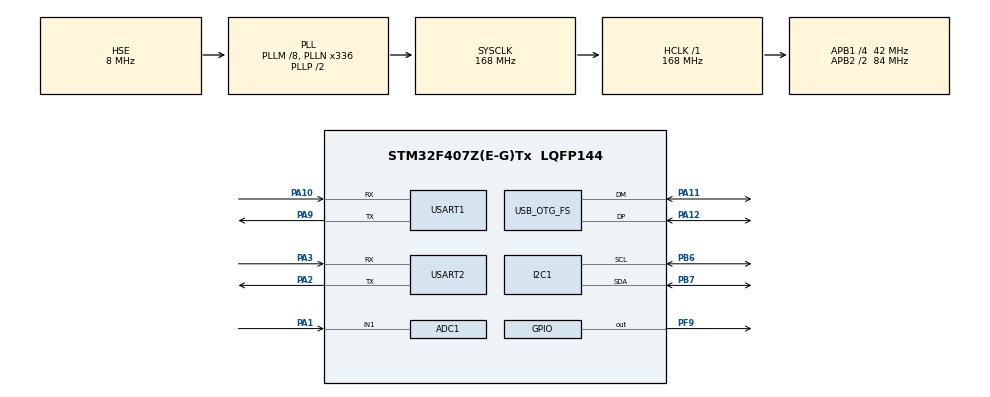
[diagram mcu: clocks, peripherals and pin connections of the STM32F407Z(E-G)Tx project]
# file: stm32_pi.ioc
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ADC1.Channel-0\#ChannelRegularConversion=ADC_CHANNEL_1
ADC1.InjNumberOfConversion=0
ADC1.NbrOfConversionFlag=1
ADC1.Rank-0\#ChannelRegularConversion=1
ADC1.SamplingTime-0\#ChannelRegularConversion=ADC_SAMPLETIME_144CYCLES
ADC1.master=1
Dma.Request0=USART1_TX
Dma.Request1=USART2_TX
Dma.USART1_TX.0.Direction=DMA_MEMORY_TO_PERIPH
Dma.USART1_TX.0.FIFOMode=DMA_FIFOMODE_DISABLE
Dma.USART1_TX.0.Instance=DMA2_Stream7
Dma.USART1_TX.0.MemDataAlignment=DMA_MDATAALIGN_BYTE
Dma.USART1_TX.0.MemInc=DMA_MINC_ENABLE
Dma.USART1_TX.0.Mode=DMA_NORMAL
Dma.USART1_TX.0.PeriphDataAlignment=DMA_PDATAALIGN_BYTE
Dma.USART1_TX.0.PeriphInc=DMA_PINC_DISABLE
Dma.USART1_TX.0.Priority=DMA_PRIORITY_LOW
Dma.USART2_TX.1.Direction=DMA_MEMORY_TO_PERIPH
Dma.USART2_TX.1.FIFOMode=DMA_FIFOMODE_DISABLE
Dma.USART2_TX.1.Instance=DMA1_Stream6
Dma.USART2_TX.1.MemDataAlignment=DMA_MDATAALIGN_BYTE
Dma.USART2_TX.1.MemInc=DMA_MINC_ENABLE
Dma.USART2_TX.1.Mode=DMA_NORMAL
Dma.USART2_TX.1.PeriphDataAlignment=DMA_PDATAALIGN_BYTE
Dma.USART2_TX.1.PeriphInc=DMA_PINC_DISABLE
Dma.USART2_TX.1.Priority=DMA_PRIORITY_LOW
FREERTOS.Tasks01=defaultTask,24,128,StartDefaultTask,Default,NULL,Dynamic,NULL,NULL
I2C1.I2C_Mode=I2C_Fast
Mcu.Family=STM32F4
Mcu.Name=STM32F407Z(E-G)Tx
Mcu.Package=LQFP144
NVIC.DMA1_Stream6_IRQn=true\:5\:0\:false\:false\:true\:true\:false\:true\:true
NVIC.DMA2_Stream7_IRQn=true\:5\:0\:false\:false\:true\:true\:false\:true\:true
NVIC.PriorityGroup=NVIC_PRIORITYGROUP_4
NVIC.TIM6_DAC_IRQn=true\:15\:0\:false\:false\:true\:false\:false\:true\:true
NVIC.TimeBase=TIM6_DAC_IRQn
NVIC.TimeBaseIP=TIM6
NVIC.USART1_IRQn=true\:5\:0\:false\:false\:true\:true\:true\:true\:true
NVIC.USART2_IRQn=true\:5\:0\:false\:false\:true\:true\:true\:true\:true
PA1.Signal=ADCx_IN1
PA10.Mode=Asynchronous
PA10.Signal=USART1_RX
PA11.Mode=Device_Only
PA11.Signal=USB_OTG_FS_DM
PA12.Mode=Device_Only
PA12.Signal=USB_OTG_FS_DP
PA13.Mode=Serial_Wire
PA13.Signal=SYS_JTMS-SWDIO
PA14.Mode=Serial_Wire
PA14.Signal=SYS_JTCK-SWCLK
PA2.Mode=Asynchronous
PA2.Signal=USART2_TX
PA3.Mode=Asynchronous
PA3.Signal=USART2_RX
PA9.Mode=Asynchronous
PA9.Signal=USART1_TX
PB6.Mode=I2C
PB6.Signal=I2C1_SCL
PB7.Mode=I2C
PB7.Signal=I2C1_SDA
PF9.Signal=GPIO_Output
PH0-OSC_IN.Mode=HSE-External-Oscillator
PH0-OSC_IN.Signal=RCC_OSC_IN
PH1-OSC_OUT.Mode=HSE-External-Oscillator
PH1-OSC_OUT.Signal=RCC_OSC_OUT
ProjectManager.HeapSize=0x200
ProjectManager.StackSize=0x400
ProjectManager.TargetToolchain=MDK-ARM V5
RCC.48MHZClocksFreq_Value=48000000
RCC.AHBFreq_Value=168000000
RCC.APB1CLKDivider=RCC_HCLK_DIV4
RCC.APB1Freq_Value=42000000
RCC.APB1TimFreq_Value=84000000
RCC.APB2CLKDivider=RCC_HCLK_DIV2
RCC.APB2Freq_Value=84000000
RCC.APB2TimFreq_Value=168000000
RCC.CortexFreq_Value=168000000
RCC.HCLKFreq_Value=168000000
RCC.HSE_VALUE=8000000
RCC.HSI_VALUE=16000000
RCC.LSE_VALUE=32768
RCC.PLLM=8
RCC.PLLN=336
RCC.PLLQ=7
RCC.SYSCLKFreq_VALUE=168000000
RCC.SYSCLKSource=RCC_SYSCLKSOURCE_PLLCLK
RCC.VCOOutputFreq_Value=336000000
SH.ADCx_IN1.0=ADC1_IN1,IN1
USART1.VirtualMode=VM_ASYNC
USART2.VirtualMode=VM_ASYNC
USB_OTG_FS.VirtualMode=Device_Only
VP_FREERTOS_VS_CMSIS_V2.Mode=CMSIS_V2
VP_SYS_VS_tim6.Mode=TIM6
board=custom

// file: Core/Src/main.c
/* USER CODE BEGIN Header */
/**
  ******************************************************************************
  * @file           : main.c
  * @brief          : Main program body
  ******************************************************************************
  * @attention
  *
  * Copyright (c) 2026 STMicroelectronics.
  * All rights reserved.
  *
  * This software is licensed under terms that can be found in the LICENSE file
  * in the root directory of this software component.
  * If no LICENSE file comes with this software, it is provided AS-IS.
  *
  ******************************************************************************
  */
/* USER CODE END Header */
#include "main.h"
#include "cmsis_os.h"

/* USER CODE BEGIN Includes */
#include "app_main.h"
/* USER CODE END Includes */

ADC_HandleTypeDef hadc1;

I2C_HandleTypeDef hi2c1;

UART_HandleTypeDef huart1;
UART_HandleTypeDef huart2;
DMA_HandleTypeDef hdma_usart1_tx;
DMA_HandleTypeDef hdma_usart2_tx;

PCD_HandleTypeDef hpcd_USB_OTG_FS;

/* Definitions for defaultTask */
osThreadId_t defaultTaskHandle;
const osThreadAttr_t defaultTask_attributes = {
  .name = "defaultTask",
  .stack_size = 128 * 4,
  .priority = (osPriority_t) osPriorityNormal,
};

void SystemClock_Config(void);
static void MX_GPIO_Init(void);
static void MX_DMA_Init(void);
static void MX_USART1_UART_Init(void);
static void MX_USB_OTG_FS_PCD_Init(void);
static void MX_USART2_UART_Init(void);
static void MX_ADC1_Init(void);
static void MX_I2C1_Init(void);
void StartDefaultTask(void *argument);

int main(void)
{

  /* MCU Configuration--------------------------------------------------------*/

  /* Reset of all peripherals, Initializes the Flash interface and the Systick. */
  HAL_Init();

  /* Configure the system clock */
  SystemClock_Config();

  /* Initialize all configured peripherals */
  MX_GPIO_Init();
  MX_DMA_Init();
  MX_USART1_UART_Init();
  MX_USB_OTG_FS_PCD_Init();
  MX_USART2_UART_Init();
  MX_ADC1_Init();
  MX_I2C1_Init();

  /* Init scheduler */
  osKernelInitialize();

  /* Create the thread(s) */
  /* creation of defaultTask */
  defaultTaskHandle = osThreadNew(StartDefaultTask, NULL, &defaultTask_attributes);

  /* USER CODE BEGIN RTOS_THREADS */
  /* add threads, ... */
  App_Main_Init();
  /* USER CODE END RTOS_THREADS */

  /* Start scheduler */
  osKernelStart();
  /* We should never get here as control is now taken by the scheduler */
  /* Infinite loop */
  while (1)
  {

  }
}

void SystemClock_Config(void)
{
  RCC_OscInitTypeDef RCC_OscInitStruct = {0};
  RCC_ClkInitTypeDef RCC_ClkInitStruct = {0};

  /** Configure the main internal regulator output voltage
  */
  __HAL_RCC_PWR_CLK_ENABLE();
  __HAL_PWR_VOLTAGESCALING_CONFIG(PWR_REGULATOR_VOLTAGE_SCALE1);

  /** Initializes the RCC Oscillators according to the specified parameters
  * in the RCC_OscInitTypeDef structure.
  */
  RCC_OscInitStruct.OscillatorType = RCC_OSCILLATORTYPE_HSE;
  RCC_OscInitStruct.HSEState = RCC_HSE_ON;
  RCC_OscInitStruct.PLL.PLLState = RCC_PLL_ON;
  RCC_OscInitStruct.PLL.PLLSource = RCC_PLLSOURCE_HSE;
  RCC_OscInitStruct.PLL.PLLM = 8;
  RCC_OscInitStruct.PLL.PLLN = 336;
  RCC_OscInitStruct.PLL.PLLP = RCC_PLLP_DIV2;
  RCC_OscInitStruct.PLL.PLLQ = 7;
  if (HAL_RCC_OscConfig(&RCC_OscInitStruct) != HAL_OK)
  {
    Error_Handler();
  }

  /** Initializes the CPU, AHB and APB buses clocks
  */
  RCC_ClkInitStruct.ClockType = RCC_CLOCKTYPE_HCLK|RCC_CLOCKTYPE_SYSCLK
                              |RCC_CLOCKTYPE_PCLK1|RCC_CLOCKTYPE_PCLK2;
  RCC_ClkInitStruct.SYSCLKSource = RCC_SYSCLKSOURCE_PLLCLK;
  RCC_ClkInitStruct.AHBCLKDivider = RCC_SYSCLK_DIV1;
  RCC_ClkInitStruct.APB1CLKDivider = RCC_HCLK_DIV4;
  RCC_ClkInitStruct.APB2CLKDivider = RCC_HCLK_DIV2;

  if (HAL_RCC_ClockConfig(&RCC_ClkInitStruct, FLASH_LATENCY_5) != HAL_OK)
  {
    Error_Handler();
  }
}

static void MX_ADC1_Init(void)
{

  ADC_ChannelConfTypeDef sConfig = {0};

  /** Configure the global features of the ADC (Clock, Resolution, Data Alignment and number of conversion)
  */
  hadc1.Instance = ADC1;
  hadc1.Init.ClockPrescaler = ADC_CLOCK_SYNC_PCLK_DIV4;
  hadc1.Init.Resolution = ADC_RESOLUTION_12B;
  hadc1.Init.ScanConvMode = DISABLE;
  hadc1.Init.ContinuousConvMode = DISABLE;
  hadc1.Init.DiscontinuousConvMode = DISABLE;
  hadc1.Init.ExternalTrigConvEdge = ADC_EXTERNALTRIGCONVEDGE_NONE;
  hadc1.Init.ExternalTrigConv = ADC_SOFTWARE_START;
  hadc1.Init.DataAlign = ADC_DATAALIGN_RIGHT;
  hadc1.Init.NbrOfConversion = 1;
  hadc1.Init.DMAContinuousRequests = DISABLE;
  hadc1.Init.EOCSelection = ADC_EOC_SINGLE_CONV;
  if (HAL_ADC_Init(&hadc1) != HAL_OK)
  {
    Error_Handler();
  }

  /** Configure for the selected ADC regular channel its corresponding rank in the sequencer and its sample time.
  */
  sConfig.Channel = ADC_CHANNEL_1;
  sConfig.Rank = 1;
  sConfig.SamplingTime = ADC_SAMPLETIME_144CYCLES;
  if (HAL_ADC_ConfigChannel(&hadc1, &sConfig) != HAL_OK)
  {
    Error_Handler();
  }

}

static void MX_I2C1_Init(void)
{

  hi2c1.Instance = I2C1;
  hi2c1.Init.ClockSpeed = 400000;
  hi2c1.Init.DutyCycle = I2C_DUTYCYCLE_2;
  hi2c1.Init.OwnAddress1 = 0;
  hi2c1.Init.AddressingMode = I2C_ADDRESSINGMODE_7BIT;
  hi2c1.Init.DualAddressMode = I2C_DUALADDRESS_DISABLE;
  hi2c1.Init.OwnAddress2 = 0;
  hi2c1.Init.GeneralCallMode = I2C_GENERALCALL_DISABLE;
  hi2c1.Init.NoStretchMode = I2C_NOSTRETCH_DISABLE;
  if (HAL_I2C_Init(&hi2c1) != HAL_OK)
  {
    Error_Handler();
  }

}

static void MX_USART1_UART_Init(void)
{

  huart1.Instance = USART1;
  huart1.Init.BaudRate = 115200;
  huart1.Init.WordLength = UART_WORDLENGTH_8B;
  huart1.Init.StopBits = UART_STOPBITS_1;
  huart1.Init.Parity = UART_PARITY_NONE;
  huart1.Init.Mode = UART_MODE_TX_RX;
  huart1.Init.HwFlowCtl = UART_HWCONTROL_NONE;
  huart1.Init.OverSampling = UART_OVERSAMPLING_16;
  if (HAL_UART_Init(&huart1) != HAL_OK)
  {
    Error_Handler();
  }

}

static void MX_USART2_UART_Init(void)
{

  huart2.Instance = USART2;
  huart2.Init.BaudRate = 115200;
  huart2.Init.WordLength = UART_WORDLENGTH_8B;
  huart2.Init.StopBits = UART_STOPBITS_1;
  huart2.Init.Parity = UART_PARITY_NONE;
  huart2.Init.Mode = UART_MODE_TX_RX;
  huart2.Init.HwFlowCtl = UART_HWCONTROL_NONE;
  huart2.Init.OverSampling = UART_OVERSAMPLING_16;
  if (HAL_UART_Init(&huart2) != HAL_OK)
  {
    Error_Handler();
  }

}

static void MX_USB_OTG_FS_PCD_Init(void)
{

  hpcd_USB_OTG_FS.Instance = USB_OTG_FS;
  hpcd_USB_OTG_FS.Init.dev_endpoints = 4;
  hpcd_USB_OTG_FS.Init.speed = PCD_SPEED_FULL;
  hpcd_USB_OTG_FS.Init.dma_enable = DISABLE;
  hpcd_USB_OTG_FS.Init.phy_itface = PCD_PHY_EMBEDDED;
  hpcd_USB_OTG_FS.Init.Sof_enable = DISABLE;
  hpcd_USB_OTG_FS.Init.low_power_enable = DISABLE;
  hpcd_USB_OTG_FS.Init.lpm_enable = DISABLE;
  hpcd_USB_OTG_FS.Init.vbus_sensing_enable = DISABLE;
  hpcd_USB_OTG_FS.Init.use_dedicated_ep1 = DISABLE;
  if (HAL_PCD_Init(&hpcd_USB_OTG_FS) != HAL_OK)
  {
    Error_Handler();
  }

}

static void MX_DMA_Init(void)
{

  /* DMA controller clock enable */
  __HAL_RCC_DMA2_CLK_ENABLE();
  __HAL_RCC_DMA1_CLK_ENABLE();

  /* DMA interrupt init */
  /* DMA1_Stream6_IRQn interrupt configuration */
  HAL_NVIC_SetPriority(DMA1_Stream6_IRQn, 5, 0);
  HAL_NVIC_EnableIRQ(DMA1_Stream6_IRQn);
  /* DMA2_Stream7_IRQn interrupt configuration */
  HAL_NVIC_SetPriority(DMA2_Stream7_IRQn, 5, 0);
  HAL_NVIC_EnableIRQ(DMA2_Stream7_IRQn);

}

static void MX_GPIO_Init(void)
{
  GPIO_InitTypeDef GPIO_InitStruct = {0};

  /* GPIO Ports Clock Enable */
  __HAL_RCC_GPIOF_CLK_ENABLE();
  __HAL_RCC_GPIOH_CLK_ENABLE();
  __HAL_RCC_GPIOA_CLK_ENABLE();
  __HAL_RCC_GPIOB_CLK_ENABLE();

  /*Configure GPIO pin Output Level */
  HAL_GPIO_WritePin(GPIOF, GPIO_PIN_9, GPIO_PIN_RESET);

  /*Configure GPIO pin : PF9 */
  GPIO_InitStruct.Pin = GPIO_PIN_9;
  GPIO_InitStruct.Mode = GPIO_MODE_OUTPUT_PP;
  GPIO_InitStruct.Pull = GPIO_NOPULL;
  GPIO_InitStruct.Speed = GPIO_SPEED_FREQ_LOW;
  HAL_GPIO_Init(GPIOF, &GPIO_InitStruct);

}

void StartDefaultTask(void *argument)
{
  /* USER CODE BEGIN 5 */
  /* Infinite loop */
  for(;;)
  {
    /* Day 1 acceptance: LED0 (PF9) blinks at 500 ms while the five
     * application tasks run alongside. */
    HAL_GPIO_TogglePin(GPIOF, GPIO_PIN_9);
    osDelay(500);
  }
  /* USER CODE END 5 */
}

void HAL_TIM_PeriodElapsedCallback(TIM_HandleTypeDef *htim)
{
  if (htim->Instance == TIM6) {
    HAL_IncTick();
  }
}

void Error_Handler(void)
{
  __disable_irq();
  while (1)
  {
  }
}
